# STM32F745IEK6 register map
File version: 1.0
Registers are 32-bit, access not given, reset 0x0 unless marked. A register's access mark holds for its fields unless they carry their own. Offsets are from the block's base; [hi:lo] are bit positions; {n}, {i} and the like mark numbered series.

## LTDC
Base 0x40016800
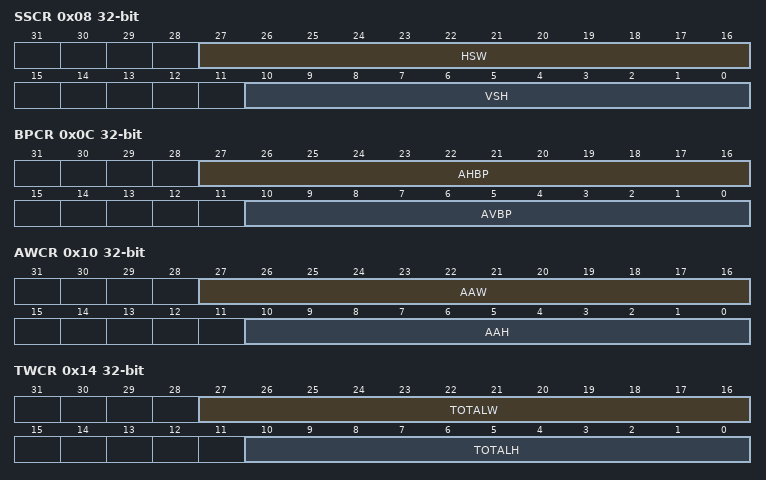
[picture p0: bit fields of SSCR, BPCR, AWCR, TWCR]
0x08 SSCR
  [27:16] HSW, [10:0] VSH
0x0C BPCR
  [27:16] AHBP, [10:0] AVBP
0x10 AWCR
  [27:16] AAW, [10:0] AAH
0x14 TWCR
  [27:16] TOTALW, [10:0] TOTALH
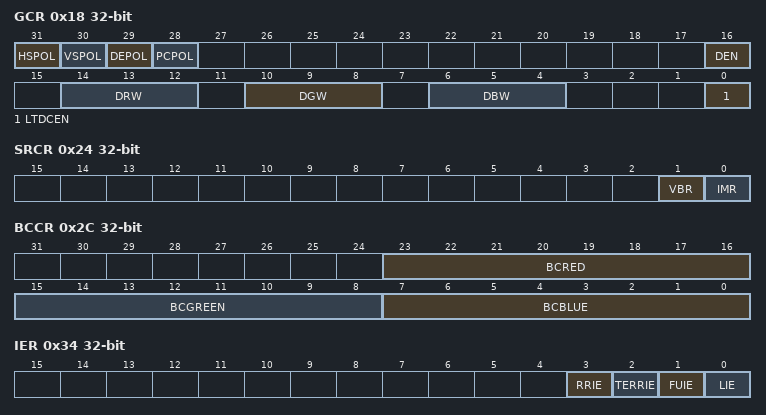
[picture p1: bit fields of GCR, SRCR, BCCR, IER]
0x18 GCR
  [31] HSPOL, [30] VSPOL, [29] DEPOL, [28] PCPOL, [16] DEN, [14:12] DRW, [10:8] DGW, [6:4] DBW, [0] LTDCEN
0x24 SRCR
  [1] VBR, [0] IMR
0x2C BCCR
  [23:16] BCRED, [15:8] BCGREEN, [7:0] BCBLUE
0x34 IER
  [3] RRIE, [2] TERRIE, [1] FUIE, [0] LIE
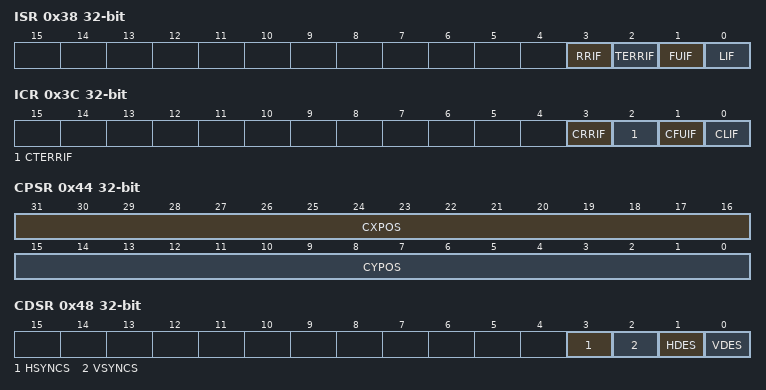
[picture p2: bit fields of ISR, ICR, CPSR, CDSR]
0x38 ISR
  [3] RRIF, [2] TERRIF, [1] FUIF, [0] LIF
0x3C ICR
  [3] CRRIF, [2] CTERRIF, [1] CFUIF, [0] CLIF
0x40 LIPCR
  [10:0] LIPOS
0x44 CPSR
  [31:16] CXPOS, [15:0] CYPOS
0x48 CDSR
  [3] HSYNCS, [2] VSYNCS, [1] HDES, [0] VDES
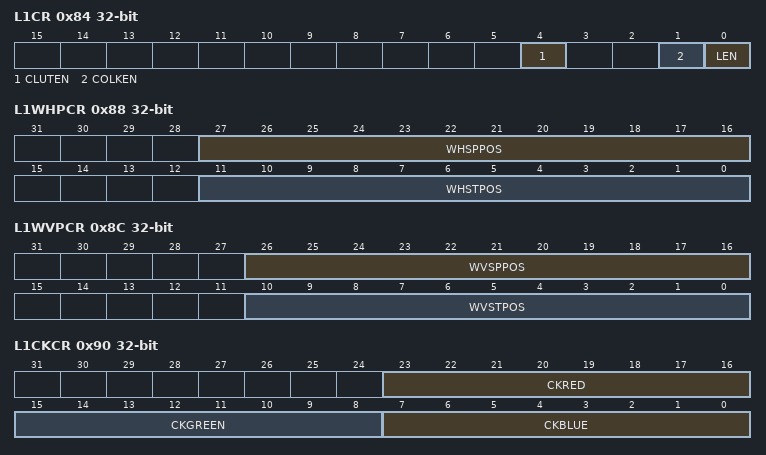
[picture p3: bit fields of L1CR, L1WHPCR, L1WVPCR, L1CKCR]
0x84 L1CR
  [4] CLUTEN, [1] COLKEN, [0] LEN
0x88 L1WHPCR
  [27:16] WHSPPOS, [11:0] WHSTPOS
0x8C L1WVPCR
  [26:16] WVSPPOS, [10:0] WVSTPOS
0x90 L1CKCR
  [23:16] CKRED, [15:8] CKGREEN, [7:0] CKBLUE
0x94 L1PFCR
  [2:0] PF
0x98 L1CACR
  [7:0] CONSTA
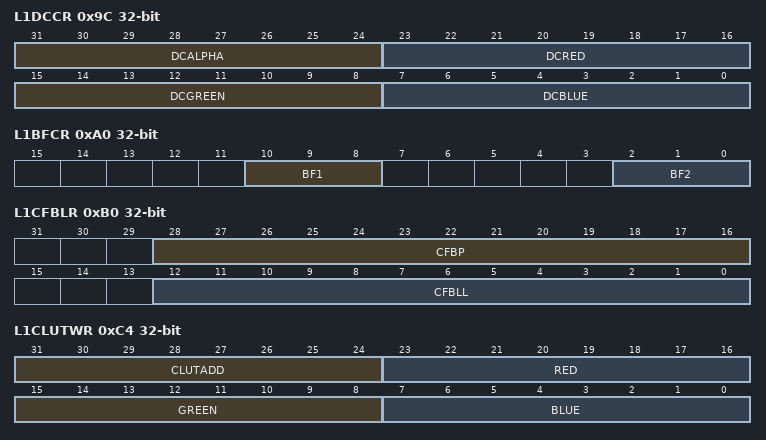
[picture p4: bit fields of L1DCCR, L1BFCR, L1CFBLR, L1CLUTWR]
0x9C L1DCCR
  [31:24] DCALPHA, [23:16] DCRED, [15:8] DCGREEN, [7:0] DCBLUE
0xA0 L1BFCR
  [10:8] BF1, [2:0] BF2
0xAC L1CFBAR
  [31:0] CFBADD
0xB0 L1CFBLR
  [28:16] CFBP, [12:0] CFBLL
0xB4 L1CFBLNR
  [10:0] CFBLNBR
0xC4 L1CLUTWR
  [31:24] CLUTADD, [23:16] RED, [15:8] GREEN, [7:0] BLUE
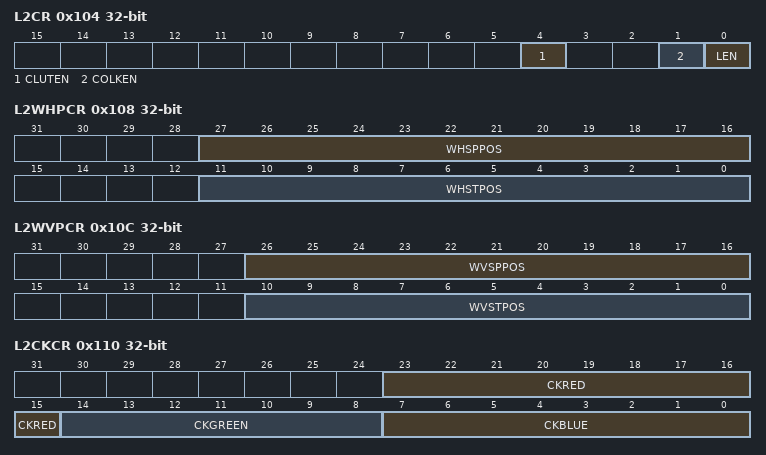
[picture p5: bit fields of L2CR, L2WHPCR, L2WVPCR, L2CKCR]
0x104 L2CR
  [4] CLUTEN, [1] COLKEN, [0] LEN
0x108 L2WHPCR
  [27:16] WHSPPOS, [11:0] WHSTPOS
0x10C L2WVPCR
  [26:16] WVSPPOS, [10:0] WVSTPOS
0x110 L2CKCR
  [23:15] CKRED, [14:8] CKGREEN, [7:0] CKBLUE
0x114 L2PFCR
  [2:0] PF
0x118 L2CACR
  [7:0] CONSTA
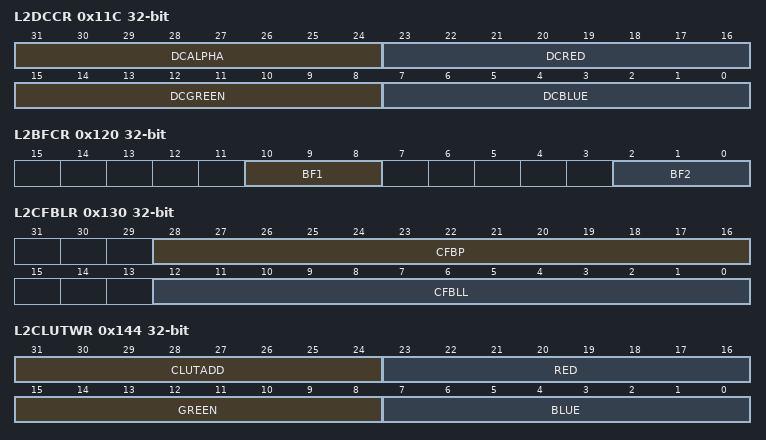
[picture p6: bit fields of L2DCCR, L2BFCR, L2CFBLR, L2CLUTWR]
0x11C L2DCCR
  [31:24] DCALPHA, [23:16] DCRED, [15:8] DCGREEN, [7:0] DCBLUE
0x120 L2BFCR
  [10:8] BF1, [2:0] BF2
0x12C L2CFBAR
  [31:0] CFBADD
0x130 L2CFBLR
  [28:16] CFBP, [12:0] CFBLL
0x134 L2CFBLNR
  [10:0] CFBLNBR
0x144 L2CLUTWR
  [31:24] CLUTADD, [23:16] RED, [15:8] GREEN, [7:0] BLUE

## GPIOA
Base 0x40020000
Same registers: GPIOB 0x40020400, GPIOC 0x40020800, GPIOD 0x40020C00, GPIOE 0x40021000, GPIOF 0x40021400, GPIOG 0x40021800, GPIOH 0x40021C00, GPIOI 0x40022000, GPIOJ 0x40022400, GPIOK 0x40022800
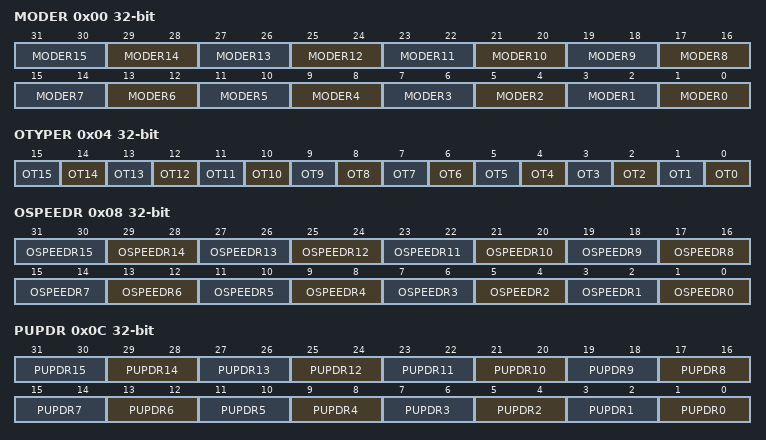
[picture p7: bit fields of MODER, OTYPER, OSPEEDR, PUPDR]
0x00 MODER
  [2n+1:2n] MODER{n} (n=0..15)
0x04 OTYPER
  [n] OT{n} (n=0..15)
0x08 OSPEEDR
  [2n+1:2n] OSPEEDR{n} (n=0..15)
0x0C PUPDR
  [2n+1:2n] PUPDR{n} (n=0..15)
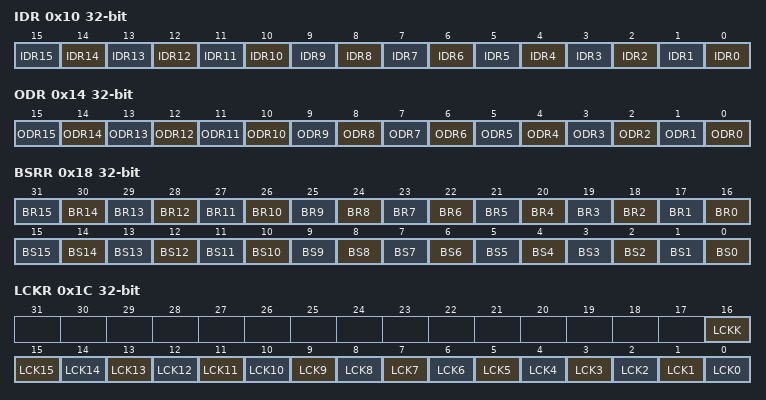
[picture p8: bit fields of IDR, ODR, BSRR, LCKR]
0x10 IDR
  [n] IDR{n} (n=0..15)
0x14 ODR
  [n] ODR{n} (n=0..15)
0x18 BSRR
  [n+16] BR{n} (n=0..15), [n] BS{n} (n=0..15)
0x1C LCKR
  [16] LCKK, [n] LCK{n} (n=0..15)
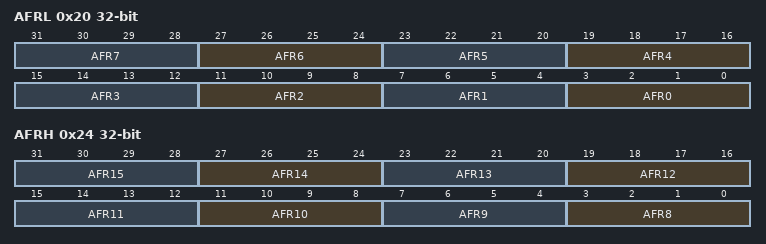
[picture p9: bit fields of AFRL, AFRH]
0x20 AFRL
  [4n+3:4n] AFR{n} (n=0..7)
0x24 AFRH
  [4n-29:4n-32] AFR{n} (n=8..15)

## CRC
Base 0x40023000
0x00 DR
0x04 IDR
  [7:0] IDR
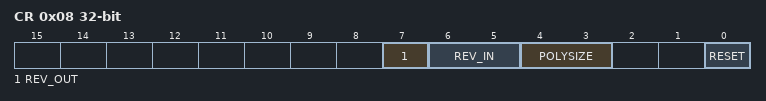
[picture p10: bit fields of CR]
0x08 CR
  [7] REV_OUT, [6:5] REV_IN, [4:3] POLYSIZE, [0] RESET
0x10 INIT
  [31:0] CRC_INIT
0x14 POL
  [31:0] Polynomialcoefficients

## FLASH
Base 0x40023C00
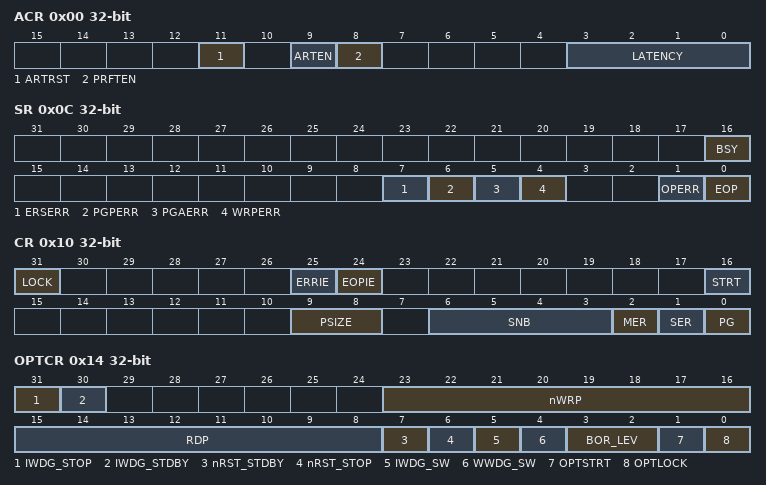
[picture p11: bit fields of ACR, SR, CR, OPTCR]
0x00 ACR
  [11] ARTRST, [9] ARTEN, [8] PRFTEN, [3:0] LATENCY
0x04 KEYR
  [31:0] KEY
0x08 OPTKEYR
0x0C SR
  [16] BSY, [7] ERSERR, [6] PGPERR, [5] PGAERR, [4] WRPERR, [1] OPERR, [0] EOP
0x10 CR
  [31] LOCK, [25] ERRIE, [24] EOPIE, [16] STRT, [9:8] PSIZE, [6:3] SNB, [2] MER, [1] SER, [0] PG
0x14 OPTCR
  [31] IWDG_STOP, [30] IWDG_STDBY, [23:16] nWRP, [15:8] RDP, [7] nRST_STDBY, [6] nRST_STOP, [5] IWDG_SW, [4] WWDG_SW, [3:2] BOR_LEV, [1] OPTSTRT, [0] OPTLOCK
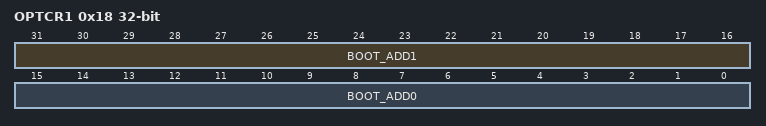
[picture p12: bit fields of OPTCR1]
0x18 OPTCR1
  [31:16] BOOT_ADD1, [15:0] BOOT_ADD0

## DMA1
Base 0x40026000
Same registers: DMA2 0x40026400
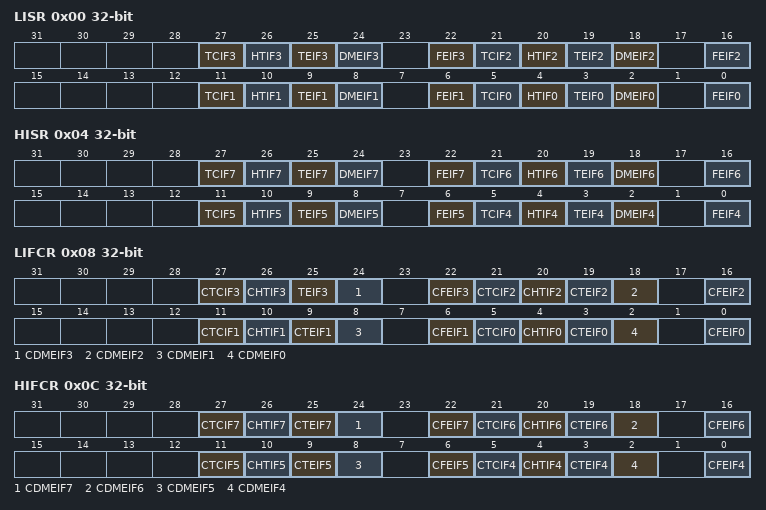
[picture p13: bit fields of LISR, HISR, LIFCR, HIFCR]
0x00 LISR
  [27] TCIF3, [26] HTIF3, [25] TEIF3, [24] DMEIF3, [22] FEIF3, [21] TCIF2, [20] HTIF2, [19] TEIF2, [18] DMEIF2, [16] FEIF2, [11] TCIF1, [10] HTIF1, [9] TEIF1, [8] DMEIF1, [6] FEIF1, [5] TCIF0, [4] HTIF0, [3] TEIF0, [2] DMEIF0, [0] FEIF0
0x04 HISR
  [27] TCIF7, [26] HTIF7, [25] TEIF7, [24] DMEIF7, [22] FEIF7, [21] TCIF6, [20] HTIF6, [19] TEIF6, [18] DMEIF6, [16] FEIF6, [11] TCIF5, [10] HTIF5, [9] TEIF5, [8] DMEIF5, [6] FEIF5, [5] TCIF4, [4] HTIF4, [3] TEIF4, [2] DMEIF4, [0] FEIF4
0x08 LIFCR
  [27] CTCIF3, [26] CHTIF3, [25] TEIF3, [24] CDMEIF3, [22] CFEIF3, [21] CTCIF2, [20] CHTIF2, [19] CTEIF2, [18] CDMEIF2, [16] CFEIF2, [11] CTCIF1, [10] CHTIF1, [9] CTEIF1, [8] CDMEIF1, [6] CFEIF1, [5] CTCIF0, [4] CHTIF0, [3] CTEIF0, [2] CDMEIF0, [0] CFEIF0
0x0C HIFCR
  [27] CTCIF7, [26] CHTIF7, [25] CTEIF7, [24] CDMEIF7, [22] CFEIF7, [21] CTCIF6, [20] CHTIF6, [19] CTEIF6, [18] CDMEIF6, [16] CFEIF6, [11] CTCIF5, [10] CHTIF5, [9] CTEIF5, [8] CDMEIF5, [6] CFEIF5, [5] CTCIF4, [4] CHTIF4, [3] CTEIF4, [2] CDMEIF4, [0] CFEIF4
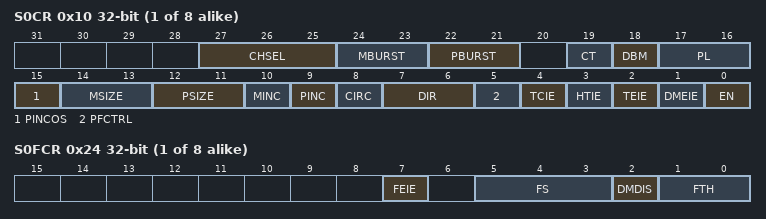
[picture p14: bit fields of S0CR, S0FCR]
{0x10+0x18*i} S{i}CR (i=0..7)
  [27:25] CHSEL, [24:23] MBURST, [22:21] PBURST, [19] CT, [18] DBM, [17:16] PL, [15] PINCOS, [14:13] MSIZE, [12:11] PSIZE, [10] MINC, [9] PINC, [8] CIRC, [7:6] DIR, [5] PFCTRL, [4] TCIE, [3] HTIE, [2] TEIE, [1] DMEIE, [0] EN
{0x14+0x18*i} S{i}NDTR (i=0..7)
  [15:0] NDT
{0x18+0x18*i} S{i}PAR (i=0..7)
  [31:0] PA
{0x1C+0x18*i} S{i}M0AR (i=0..7)
  [31:0] M0A
{0x20+0x18*i} S{i}M1AR (i=0..7)
  [31:0] M1A
{0x24+0x18*i} S{i}FCR (i=0..7)
  [7] FEIE, [5:3] FS, [2] DMDIS, [1:0] FTH
